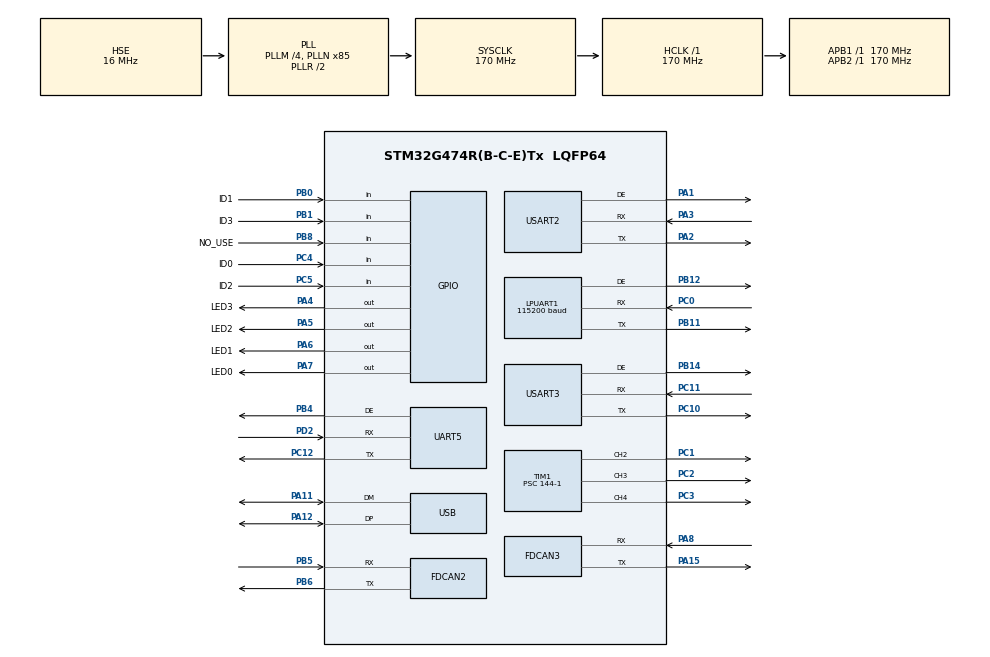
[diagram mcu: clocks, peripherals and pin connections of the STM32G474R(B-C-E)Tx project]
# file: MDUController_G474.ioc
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FDCAN2.CalculateBaudRateNominal=999999
FDCAN2.CalculateTimeBitNominal=1000
FDCAN2.CalculateTimeQuantumNominal=29.411764705882355
FDCAN2.ExtFiltersNbr=1
FDCAN2.Mode=FDCAN_MODE_NORMAL
FDCAN2.NominalPrescaler=5
FDCAN2.NominalTimeSeg1=19
FDCAN2.NominalTimeSeg2=14
FDCAN2.StdFiltersNbr=1
FDCAN3.CalculateBaudRateNominal=999999
FDCAN3.CalculateTimeBitNominal=1000
FDCAN3.CalculateTimeQuantumNominal=29.411764705882355
FDCAN3.ExtFiltersNbr=1
FDCAN3.Mode=FDCAN_MODE_NORMAL
FDCAN3.NominalPrescaler=5
FDCAN3.NominalTimeSeg1=19
FDCAN3.NominalTimeSeg2=14
FDCAN3.StdFiltersNbr=1
LPUART1.BaudRate=115200
Mcu.Family=STM32G4
Mcu.Name=STM32G474R(B-C-E)Tx
Mcu.Package=LQFP64
NVIC.FDCAN2_IT0_IRQn=true\:0\:0\:false\:false\:true\:true\:true\:true
NVIC.FDCAN2_IT1_IRQn=true\:0\:0\:false\:false\:true\:true\:true\:true
NVIC.FDCAN3_IT0_IRQn=true\:0\:0\:false\:false\:true\:true\:true\:true
NVIC.FDCAN3_IT1_IRQn=true\:0\:0\:false\:false\:true\:true\:true\:true
NVIC.LPUART1_IRQn=true\:0\:0\:false\:false\:true\:true\:true\:true
NVIC.PriorityGroup=NVIC_PRIORITYGROUP_4
NVIC.TIM1_BRK_TIM15_IRQn=true\:0\:0\:false\:false\:true\:true\:true\:true
NVIC.TIM1_TRG_COM_TIM17_IRQn=true\:0\:0\:false\:false\:true\:true\:true\:true
NVIC.TIM1_UP_TIM16_IRQn=true\:0\:0\:false\:false\:true\:true\:true\:true
NVIC.TIM2_IRQn=true\:0\:0\:false\:false\:true\:true\:true\:true
NVIC.UART5_IRQn=true\:0\:0\:false\:false\:true\:true\:true\:true
NVIC.USART2_IRQn=true\:0\:0\:false\:false\:true\:true\:true\:true
NVIC.USART3_IRQn=true\:0\:0\:false\:false\:true\:true\:true\:true
NVIC.USB_HP_IRQn=true\:0\:0\:false\:false\:true\:true\:true\:true
NVIC.USB_LP_IRQn=true\:0\:0\:false\:false\:true\:false\:true\:true
PA1.Mode=Hardware Flow Control (RS485)
PA1.Signal=USART2_DE
PA11.Mode=Device
PA11.Signal=USB_DM
PA12.Mode=Device
PA12.Signal=USB_DP
PA13.Signal=SYS_JTMS-SWDIO
PA14.Signal=SYS_JTCK-SWCLK
PA15.Mode=FDCAN_Activate
PA15.Signal=FDCAN3_TX
PA2.Mode=Asynchronous
PA2.Signal=USART2_TX
PA3.Mode=Asynchronous
PA3.Signal=USART2_RX
PA4.GPIO_Label=LED3
PA4.Signal=GPIO_Output
PA5.GPIO_Label=LED2
PA5.Signal=GPIO_Output
PA6.GPIO_Label=LED1
PA6.Signal=GPIO_Output
PA7.GPIO_Label=LED0
PA7.Signal=GPIO_Output
PA8.Mode=FDCAN_Activate
PA8.Signal=FDCAN3_RX
PB0.GPIO_Label=ID1
PB0.GPIO_PuPd=GPIO_PULLUP
PB0.Signal=GPIO_Input
PB1.GPIO_Label=ID3
PB1.GPIO_PuPd=GPIO_PULLUP
PB1.Signal=GPIO_Input
PB11.Mode=Asynchronous
PB11.Signal=LPUART1_TX
PB12.Mode=Hardware Flow Control (RS485)
PB12.Signal=LPUART1_DE
PB14.Mode=Hardware Flow Control (RS485)
PB14.Signal=USART3_DE
PB4.Mode=Hardware Flow Control (RS485)
PB4.Signal=UART5_DE
PB5.Mode=FDCAN_Activate
PB5.Signal=FDCAN2_RX
PB6.Mode=FDCAN_Activate
PB6.Signal=FDCAN2_TX
PB8-BOOT0.GPIO_Label=NO_USE
PB8-BOOT0.GPIO_PuPd=GPIO_NOPULL
PB8-BOOT0.Signal=GPIO_Input
PC0.Mode=Asynchronous
PC0.Signal=LPUART1_RX
PC1.Signal=S_TIM1_CH2
PC10.Mode=Asynchronous
PC10.Signal=USART3_TX
PC11.Mode=Asynchronous
PC11.Signal=USART3_RX
PC12.Mode=Asynchronous
PC12.Signal=UART5_TX
PC2.Signal=S_TIM1_CH3
PC3.Signal=S_TIM1_CH4
PC4.GPIO_Label=ID0
PC4.GPIO_PuPd=GPIO_PULLUP
PC4.Signal=GPIO_Input
PC5.GPIO_Label=ID2
PC5.GPIO_PuPd=GPIO_PULLUP
PC5.Signal=GPIO_Input
PD2.Mode=Asynchronous
PD2.Signal=UART5_RX
PF0-OSC_IN.Mode=HSE-External-Oscillator
PF0-OSC_IN.Signal=RCC_OSC_IN
PF1-OSC_OUT.Mode=HSE-External-Oscillator
PF1-OSC_OUT.Signal=RCC_OSC_OUT
ProjectManager.HeapSize=0x200
ProjectManager.StackSize=0x400
ProjectManager.TargetToolchain=STM32CubeIDE
RCC.ADC12Freq_Value=170000000
RCC.ADC345Freq_Value=170000000
RCC.AHBFreq_Value=170000000
RCC.APB1Freq_Value=170000000
RCC.APB1TimFreq_Value=170000000
RCC.APB2Freq_Value=170000000
RCC.APB2TimFreq_Value=170000000
RCC.CK48CLockSelection=RCC_USBCLKSOURCE_HSI48
RCC.CortexFreq_Value=170000000
RCC.EXTERNAL_CLOCK_VALUE=12288000
RCC.HCLKFreq_Value=170000000
RCC.HSE_VALUE=16000000
RCC.HSI48_VALUE=48000000
RCC.HSI_VALUE=16000000
RCC.LSE_VALUE=32768
RCC.PLLM=RCC_PLLM_DIV4
RCC.PLLN=85
RCC.PLLQ=RCC_PLLQ_DIV6
RCC.PLLSourceVirtual=RCC_PLLSOURCE_HSE
RCC.SYSCLKFreq_VALUE=170000000
RCC.SYSCLKSource=RCC_SYSCLKSOURCE_PLLCLK
RCC.USBFreq_Value=48000000
RCC.VCOOutputFreq_Value=340000000
SH.S_TIM1_CH2.0=TIM1_CH2,PWM Generation2 CH2
SH.S_TIM1_CH3.0=TIM1_CH3,PWM Generation3 CH3
SH.S_TIM1_CH4.0=TIM1_CH4,PWM Generation4 CH4
TIM1.Channel-PWM\ Generation1\ CH1=TIM_CHANNEL_1
TIM1.Channel-PWM\ Generation2\ CH2=TIM_CHANNEL_2
TIM1.Channel-PWM\ Generation3\ CH3=TIM_CHANNEL_3
TIM1.Channel-PWM\ Generation4\ CH4=TIM_CHANNEL_4
TIM1.OCMode_PWM-PWM\ Generation2\ CH2=TIM_OCMODE_PWM2
TIM1.OCMode_PWM-PWM\ Generation3\ CH3=TIM_OCMODE_PWM2
TIM1.OCMode_PWM-PWM\ Generation4\ CH4=TIM_OCMODE_PWM2
TIM1.OCPolarity_2=TIM_OCPOLARITY_LOW
TIM1.OCPolarity_3=TIM_OCPOLARITY_LOW
TIM1.OCPolarity_4=TIM_OCPOLARITY_LOW
TIM1.Prescaler=144-1
TIM15.Prescaler=17000-1
TIM16.Prescaler=17000-1
TIM17.Prescaler=17000-1
TIM2.Prescaler=17000-1
USART2.VirtualMode-Asynchronous=VM_ASYNC
USART2.VirtualMode-Hardware\ Flow\ Control\ (RS485)=VM_ASYNC
USART3.VirtualMode-Asynchronous=VM_ASYNC
USART3.VirtualMode-Hardware\ Flow\ Control\ (RS485)=VM_ASYNC
USB_DEVICE.CLASS_NAME_FS=CDC
USB_DEVICE.LANGID_STRING=1033
USB_DEVICE.MANUFACTURER_STRING=Robopro
USB_DEVICE.PRODUCT_STRING_CDC_FS=MDUController2
USB_DEVICE.VirtualMode=Cdc
USB_DEVICE.VirtualModeFS=Cdc_FS
VP_SYS_VS_DBSignals.Mode=DisableDeadBatterySignals
VP_TIM15_VS_ClockSourceINT.Mode=Internal
VP_TIM16_VS_ClockSourceINT.Mode=Enable_Timer
VP_TIM17_VS_ClockSourceINT.Mode=Enable_Timer
VP_TIM1_VS_ClockSourceINT.Mode=Internal
VP_TIM2_VS_ClockSourceINT.Mode=Internal
VP_USB_DEVICE_VS_USB_DEVICE_CDC_FS.Mode=CDC_FS
board=custom

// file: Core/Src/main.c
/* USER CODE BEGIN Header */
/**
  ******************************************************************************
  * @file           : main.c
  * @brief          : Main program body
  ******************************************************************************
  * @attention
  *
  * Copyright (c) 2025 STMicroelectronics.
  * All rights reserved.
  *
  * This software is licensed under terms that can be found in the LICENSE file
  * in the root directory of this software component.
  * If no LICENSE file comes with this software, it is provided AS-IS.
  *
  ******************************************************************************
  */
/* USER CODE END Header */
#include "main.h"
#include "usb_device.h"

/* USER CODE BEGIN Includes */
#include <stdio.h>
/* USER CODE END Includes */

FDCAN_HandleTypeDef hfdcan2;
FDCAN_HandleTypeDef hfdcan3;

UART_HandleTypeDef hlpuart1;
UART_HandleTypeDef huart5;
UART_HandleTypeDef huart2;
UART_HandleTypeDef huart3;

TIM_HandleTypeDef htim1;
TIM_HandleTypeDef htim2;
TIM_HandleTypeDef htim15;
TIM_HandleTypeDef htim16;
TIM_HandleTypeDef htim17;

void SystemClock_Config(void);
static void MX_GPIO_Init(void);
static void MX_FDCAN2_Init(void);
static void MX_UART5_Init(void);
static void MX_USART2_UART_Init(void);
static void MX_USART3_UART_Init(void);
static void MX_TIM1_Init(void);
static void MX_FDCAN3_Init(void);
static void MX_LPUART1_UART_Init(void);
static void MX_TIM15_Init(void);
static void MX_TIM16_Init(void);
static void MX_TIM17_Init(void);
static void MX_TIM2_Init(void);

int main(void)
{

  /* MCU Configuration--------------------------------------------------------*/

  /* Reset of all peripherals, Initializes the Flash interface and the Systick. */
  HAL_Init();

  /* Configure the system clock */
  SystemClock_Config();

  /* Initialize all configured peripherals */
  MX_GPIO_Init();
  MX_FDCAN2_Init();
  MX_UART5_Init();
  MX_USART2_UART_Init();
  MX_USART3_UART_Init();
  MX_USB_Device_Init();
  MX_TIM1_Init();
  MX_FDCAN3_Init();
  MX_LPUART1_UART_Init();
  MX_TIM15_Init();
  MX_TIM16_Init();
  MX_TIM17_Init();
  MX_TIM2_Init();

  /* Infinite loop */
  while (1)
  {

    /* USER CODE BEGIN 3 */
	  //メインコードはUserLib/board_main.cppに実装
	  cppmain();
  }
  /* USER CODE END 3 */
}

void SystemClock_Config(void)
{
  RCC_OscInitTypeDef RCC_OscInitStruct = {0};
  RCC_ClkInitTypeDef RCC_ClkInitStruct = {0};

  /** Configure the main internal regulator output voltage
  */
  HAL_PWREx_ControlVoltageScaling(PWR_REGULATOR_VOLTAGE_SCALE1_BOOST);

  /** Initializes the RCC Oscillators according to the specified parameters
  * in the RCC_OscInitTypeDef structure.
  */
  RCC_OscInitStruct.OscillatorType = RCC_OSCILLATORTYPE_HSI48|RCC_OSCILLATORTYPE_HSE;
  RCC_OscInitStruct.HSEState = RCC_HSE_ON;
  RCC_OscInitStruct.HSI48State = RCC_HSI48_ON;
  RCC_OscInitStruct.PLL.PLLState = RCC_PLL_ON;
  RCC_OscInitStruct.PLL.PLLSource = RCC_PLLSOURCE_HSE;
  RCC_OscInitStruct.PLL.PLLM = RCC_PLLM_DIV4;
  RCC_OscInitStruct.PLL.PLLN = 85;
  RCC_OscInitStruct.PLL.PLLP = RCC_PLLP_DIV2;
  RCC_OscInitStruct.PLL.PLLQ = RCC_PLLQ_DIV6;
  RCC_OscInitStruct.PLL.PLLR = RCC_PLLR_DIV2;
  if (HAL_RCC_OscConfig(&RCC_OscInitStruct) != HAL_OK)
  {
    Error_Handler();
  }

  /** Initializes the CPU, AHB and APB buses clocks
  */
  RCC_ClkInitStruct.ClockType = RCC_CLOCKTYPE_HCLK|RCC_CLOCKTYPE_SYSCLK
                              |RCC_CLOCKTYPE_PCLK1|RCC_CLOCKTYPE_PCLK2;
  RCC_ClkInitStruct.SYSCLKSource = RCC_SYSCLKSOURCE_PLLCLK;
  RCC_ClkInitStruct.AHBCLKDivider = RCC_SYSCLK_DIV1;
  RCC_ClkInitStruct.APB1CLKDivider = RCC_HCLK_DIV1;
  RCC_ClkInitStruct.APB2CLKDivider = RCC_HCLK_DIV1;

  if (HAL_RCC_ClockConfig(&RCC_ClkInitStruct, FLASH_LATENCY_4) != HAL_OK)
  {
    Error_Handler();
  }
}

static void MX_FDCAN2_Init(void)
{

  hfdcan2.Instance = FDCAN2;
  hfdcan2.Init.ClockDivider = FDCAN_CLOCK_DIV1;
  hfdcan2.Init.FrameFormat = FDCAN_FRAME_CLASSIC;
  hfdcan2.Init.Mode = FDCAN_MODE_NORMAL;
  hfdcan2.Init.AutoRetransmission = DISABLE;
  hfdcan2.Init.TransmitPause = DISABLE;
  hfdcan2.Init.ProtocolException = DISABLE;
  hfdcan2.Init.NominalPrescaler = 5;
  hfdcan2.Init.NominalSyncJumpWidth = 1;
  hfdcan2.Init.NominalTimeSeg1 = 19;
  hfdcan2.Init.NominalTimeSeg2 = 14;
  hfdcan2.Init.DataPrescaler = 1;
  hfdcan2.Init.DataSyncJumpWidth = 1;
  hfdcan2.Init.DataTimeSeg1 = 1;
  hfdcan2.Init.DataTimeSeg2 = 1;
  hfdcan2.Init.StdFiltersNbr = 1;
  hfdcan2.Init.ExtFiltersNbr = 1;
  hfdcan2.Init.TxFifoQueueMode = FDCAN_TX_FIFO_OPERATION;
  if (HAL_FDCAN_Init(&hfdcan2) != HAL_OK)
  {
    Error_Handler();
  }

}

static void MX_FDCAN3_Init(void)
{

  hfdcan3.Instance = FDCAN3;
  hfdcan3.Init.ClockDivider = FDCAN_CLOCK_DIV1;
  hfdcan3.Init.FrameFormat = FDCAN_FRAME_CLASSIC;
  hfdcan3.Init.Mode = FDCAN_MODE_NORMAL;
  hfdcan3.Init.AutoRetransmission = DISABLE;
  hfdcan3.Init.TransmitPause = DISABLE;
  hfdcan3.Init.ProtocolException = DISABLE;
  hfdcan3.Init.NominalPrescaler = 5;
  hfdcan3.Init.NominalSyncJumpWidth = 1;
  hfdcan3.Init.NominalTimeSeg1 = 19;
  hfdcan3.Init.NominalTimeSeg2 = 14;
  hfdcan3.Init.DataPrescaler = 1;
  hfdcan3.Init.DataSyncJumpWidth = 1;
  hfdcan3.Init.DataTimeSeg1 = 1;
  hfdcan3.Init.DataTimeSeg2 = 1;
  hfdcan3.Init.StdFiltersNbr = 1;
  hfdcan3.Init.ExtFiltersNbr = 1;
  hfdcan3.Init.TxFifoQueueMode = FDCAN_TX_FIFO_OPERATION;
  if (HAL_FDCAN_Init(&hfdcan3) != HAL_OK)
  {
    Error_Handler();
  }

}

static void MX_LPUART1_UART_Init(void)
{

  hlpuart1.Instance = LPUART1;
  hlpuart1.Init.BaudRate = 115200;
  hlpuart1.Init.WordLength = UART_WORDLENGTH_8B;
  hlpuart1.Init.StopBits = UART_STOPBITS_1;
  hlpuart1.Init.Parity = UART_PARITY_NONE;
  hlpuart1.Init.Mode = UART_MODE_TX_RX;
  hlpuart1.Init.HwFlowCtl = UART_HWCONTROL_NONE;
  hlpuart1.Init.OneBitSampling = UART_ONE_BIT_SAMPLE_DISABLE;
  hlpuart1.Init.ClockPrescaler = UART_PRESCALER_DIV1;
  hlpuart1.AdvancedInit.AdvFeatureInit = UART_ADVFEATURE_NO_INIT;
  if (HAL_UART_Init(&hlpuart1) != HAL_OK)
  {
    Error_Handler();
  }
  if (HAL_UARTEx_SetTxFifoThreshold(&hlpuart1, UART_TXFIFO_THRESHOLD_1_8) != HAL_OK)
  {
    Error_Handler();
  }
  if (HAL_UARTEx_SetRxFifoThreshold(&hlpuart1, UART_RXFIFO_THRESHOLD_1_8) != HAL_OK)
  {
    Error_Handler();
  }
  if (HAL_UARTEx_DisableFifoMode(&hlpuart1) != HAL_OK)
  {
    Error_Handler();
  }
  if (HAL_RS485Ex_Init(&hlpuart1, UART_DE_POLARITY_HIGH, 0, 0) != HAL_OK)
  {
    Error_Handler();
  }

}

static void MX_UART5_Init(void)
{

  huart5.Instance = UART5;
  huart5.Init.BaudRate = 115200;
  huart5.Init.WordLength = UART_WORDLENGTH_8B;
  huart5.Init.StopBits = UART_STOPBITS_1;
  huart5.Init.Parity = UART_PARITY_NONE;
  huart5.Init.Mode = UART_MODE_TX_RX;
  huart5.Init.HwFlowCtl = UART_HWCONTROL_NONE;
  huart5.Init.OverSampling = UART_OVERSAMPLING_16;
  huart5.Init.OneBitSampling = UART_ONE_BIT_SAMPLE_DISABLE;
  huart5.Init.ClockPrescaler = UART_PRESCALER_DIV1;
  huart5.AdvancedInit.AdvFeatureInit = UART_ADVFEATURE_NO_INIT;
  if (HAL_RS485Ex_Init(&huart5, UART_DE_POLARITY_HIGH, 0, 0) != HAL_OK)
  {
    Error_Handler();
  }
  if (HAL_UARTEx_SetTxFifoThreshold(&huart5, UART_TXFIFO_THRESHOLD_1_8) != HAL_OK)
  {
    Error_Handler();
  }
  if (HAL_UARTEx_SetRxFifoThreshold(&huart5, UART_RXFIFO_THRESHOLD_1_8) != HAL_OK)
  {
    Error_Handler();
  }
  if (HAL_UARTEx_DisableFifoMode(&huart5) != HAL_OK)
  {
    Error_Handler();
  }

}

static void MX_USART2_UART_Init(void)
{

  huart2.Instance = USART2;
  huart2.Init.BaudRate = 115200;
  huart2.Init.WordLength = UART_WORDLENGTH_8B;
  huart2.Init.StopBits = UART_STOPBITS_1;
  huart2.Init.Parity = UART_PARITY_NONE;
  huart2.Init.Mode = UART_MODE_TX_RX;
  huart2.Init.HwFlowCtl = UART_HWCONTROL_NONE;
  huart2.Init.OverSampling = UART_OVERSAMPLING_16;
  huart2.Init.OneBitSampling = UART_ONE_BIT_SAMPLE_DISABLE;
  huart2.Init.ClockPrescaler = UART_PRESCALER_DIV1;
  huart2.AdvancedInit.AdvFeatureInit = UART_ADVFEATURE_NO_INIT;
  if (HAL_RS485Ex_Init(&huart2, UART_DE_POLARITY_HIGH, 0, 0) != HAL_OK)
  {
    Error_Handler();
  }
  if (HAL_UARTEx_SetTxFifoThreshold(&huart2, UART_TXFIFO_THRESHOLD_1_8) != HAL_OK)
  {
    Error_Handler();
  }
  if (HAL_UARTEx_SetRxFifoThreshold(&huart2, UART_RXFIFO_THRESHOLD_1_8) != HAL_OK)
  {
    Error_Handler();
  }
  if (HAL_UARTEx_DisableFifoMode(&huart2) != HAL_OK)
  {
    Error_Handler();
  }

}

static void MX_USART3_UART_Init(void)
{

  huart3.Instance = USART3;
  huart3.Init.BaudRate = 115200;
  huart3.Init.WordLength = UART_WORDLENGTH_8B;
  huart3.Init.StopBits = UART_STOPBITS_1;
  huart3.Init.Parity = UART_PARITY_NONE;
  huart3.Init.Mode = UART_MODE_TX_RX;
  huart3.Init.HwFlowCtl = UART_HWCONTROL_NONE;
  huart3.Init.OverSampling = UART_OVERSAMPLING_16;
  huart3.Init.OneBitSampling = UART_ONE_BIT_SAMPLE_DISABLE;
  huart3.Init.ClockPrescaler = UART_PRESCALER_DIV1;
  huart3.AdvancedInit.AdvFeatureInit = UART_ADVFEATURE_NO_INIT;
  if (HAL_RS485Ex_Init(&huart3, UART_DE_POLARITY_HIGH, 0, 0) != HAL_OK)
  {
    Error_Handler();
  }
  if (HAL_UARTEx_SetTxFifoThreshold(&huart3, UART_TXFIFO_THRESHOLD_1_8) != HAL_OK)
  {
    Error_Handler();
  }
  if (HAL_UARTEx_SetRxFifoThreshold(&huart3, UART_RXFIFO_THRESHOLD_1_8) != HAL_OK)
  {
    Error_Handler();
  }
  if (HAL_UARTEx_DisableFifoMode(&huart3) != HAL_OK)
  {
    Error_Handler();
  }

}

static void MX_TIM1_Init(void)
{

  TIM_ClockConfigTypeDef sClockSourceConfig = {0};
  TIM_MasterConfigTypeDef sMasterConfig = {0};
  TIM_OC_InitTypeDef sConfigOC = {0};
  TIM_BreakDeadTimeConfigTypeDef sBreakDeadTimeConfig = {0};

  htim1.Instance = TIM1;
  htim1.Init.Prescaler = 144-1;
  htim1.Init.CounterMode = TIM_COUNTERMODE_UP;
  htim1.Init.Period = 65535;
  htim1.Init.ClockDivision = TIM_CLOCKDIVISION_DIV1;
  htim1.Init.RepetitionCounter = 0;
  htim1.Init.AutoReloadPreload = TIM_AUTORELOAD_PRELOAD_DISABLE;
  if (HAL_TIM_Base_Init(&htim1) != HAL_OK)
  {
    Error_Handler();
  }
  sClockSourceConfig.ClockSource = TIM_CLOCKSOURCE_INTERNAL;
  if (HAL_TIM_ConfigClockSource(&htim1, &sClockSourceConfig) != HAL_OK)
  {
    Error_Handler();
  }
  if (HAL_TIM_PWM_Init(&htim1) != HAL_OK)
  {
    Error_Handler();
  }
  sMasterConfig.MasterOutputTrigger = TIM_TRGO_RESET;
  sMasterConfig.MasterOutputTrigger2 = TIM_TRGO2_RESET;
  sMasterConfig.MasterSlaveMode = TIM_MASTERSLAVEMODE_DISABLE;
  if (HAL_TIMEx_MasterConfigSynchronization(&htim1, &sMasterConfig) != HAL_OK)
  {
    Error_Handler();
  }
  sConfigOC.OCMode = TIM_OCMODE_PWM2;
  sConfigOC.Pulse = 0;
  sConfigOC.OCPolarity = TIM_OCPOLARITY_LOW;
  sConfigOC.OCNPolarity = TIM_OCNPOLARITY_HIGH;
  sConfigOC.OCFastMode = TIM_OCFAST_DISABLE;
  sConfigOC.OCIdleState = TIM_OCIDLESTATE_RESET;
  sConfigOC.OCNIdleState = TIM_OCNIDLESTATE_RESET;
  if (HAL_TIM_PWM_ConfigChannel(&htim1, &sConfigOC, TIM_CHANNEL_2) != HAL_OK)
  {
    Error_Handler();
  }
  if (HAL_TIM_PWM_ConfigChannel(&htim1, &sConfigOC, TIM_CHANNEL_3) != HAL_OK)
  {
    Error_Handler();
  }
  if (HAL_TIM_PWM_ConfigChannel(&htim1, &sConfigOC, TIM_CHANNEL_4) != HAL_OK)
  {
    Error_Handler();
  }
  sBreakDeadTimeConfig.OffStateRunMode = TIM_OSSR_DISABLE;
  sBreakDeadTimeConfig.OffStateIDLEMode = TIM_OSSI_DISABLE;
  sBreakDeadTimeConfig.LockLevel = TIM_LOCKLEVEL_OFF;
  sBreakDeadTimeConfig.DeadTime = 0;
  sBreakDeadTimeConfig.BreakState = TIM_BREAK_DISABLE;
  sBreakDeadTimeConfig.BreakPolarity = TIM_BREAKPOLARITY_HIGH;
  sBreakDeadTimeConfig.BreakFilter = 0;
  sBreakDeadTimeConfig.BreakAFMode = TIM_BREAK_AFMODE_INPUT;
  sBreakDeadTimeConfig.Break2State = TIM_BREAK2_DISABLE;
  sBreakDeadTimeConfig.Break2Polarity = TIM_BREAK2POLARITY_HIGH;
  sBreakDeadTimeConfig.Break2Filter = 0;
  sBreakDeadTimeConfig.Break2AFMode = TIM_BREAK_AFMODE_INPUT;
  sBreakDeadTimeConfig.AutomaticOutput = TIM_AUTOMATICOUTPUT_DISABLE;
  if (HAL_TIMEx_ConfigBreakDeadTime(&htim1, &sBreakDeadTimeConfig) != HAL_OK)
  {
    Error_Handler();
  }
  HAL_TIM_MspPostInit(&htim1);

}

static void MX_TIM2_Init(void)
{

  TIM_ClockConfigTypeDef sClockSourceConfig = {0};
  TIM_MasterConfigTypeDef sMasterConfig = {0};

  htim2.Instance = TIM2;
  htim2.Init.Prescaler = 17000-1;
  htim2.Init.CounterMode = TIM_COUNTERMODE_UP;
  htim2.Init.Period = 4294967295;
  htim2.Init.ClockDivision = TIM_CLOCKDIVISION_DIV1;
  htim2.Init.AutoReloadPreload = TIM_AUTORELOAD_PRELOAD_DISABLE;
  if (HAL_TIM_Base_Init(&htim2) != HAL_OK)
  {
    Error_Handler();
  }
  sClockSourceConfig.ClockSource = TIM_CLOCKSOURCE_INTERNAL;
  if (HAL_TIM_ConfigClockSource(&htim2, &sClockSourceConfig) != HAL_OK)
  {
    Error_Handler();
  }
  sMasterConfig.MasterOutputTrigger = TIM_TRGO_RESET;
  sMasterConfig.MasterSlaveMode = TIM_MASTERSLAVEMODE_DISABLE;
  if (HAL_TIMEx_MasterConfigSynchronization(&htim2, &sMasterConfig) != HAL_OK)
  {
    Error_Handler();
  }

}

static void MX_TIM15_Init(void)
{

  TIM_ClockConfigTypeDef sClockSourceConfig = {0};
  TIM_MasterConfigTypeDef sMasterConfig = {0};

  htim15.Instance = TIM15;
  htim15.Init.Prescaler = 17000-1;
  htim15.Init.CounterMode = TIM_COUNTERMODE_UP;
  htim15.Init.Period = 65535;
  htim15.Init.ClockDivision = TIM_CLOCKDIVISION_DIV1;
  htim15.Init.RepetitionCounter = 0;
  htim15.Init.AutoReloadPreload = TIM_AUTORELOAD_PRELOAD_DISABLE;
  if (HAL_TIM_Base_Init(&htim15) != HAL_OK)
  {
    Error_Handler();
  }
  sClockSourceConfig.ClockSource = TIM_CLOCKSOURCE_INTERNAL;
  if (HAL_TIM_ConfigClockSource(&htim15, &sClockSourceConfig) != HAL_OK)
  {
    Error_Handler();
  }
  sMasterConfig.MasterOutputTrigger = TIM_TRGO_RESET;
  sMasterConfig.MasterSlaveMode = TIM_MASTERSLAVEMODE_DISABLE;
  if (HAL_TIMEx_MasterConfigSynchronization(&htim15, &sMasterConfig) != HAL_OK)
  {
    Error_Handler();
  }

}

static void MX_TIM16_Init(void)
{

  htim16.Instance = TIM16;
  htim16.Init.Prescaler = 17000-1;
  htim16.Init.CounterMode = TIM_COUNTERMODE_UP;
  htim16.Init.Period = 65535;
  htim16.Init.ClockDivision = TIM_CLOCKDIVISION_DIV1;
  htim16.Init.RepetitionCounter = 0;
  htim16.Init.AutoReloadPreload = TIM_AUTORELOAD_PRELOAD_DISABLE;
  if (HAL_TIM_Base_Init(&htim16) != HAL_OK)
  {
    Error_Handler();
  }

}

static void MX_TIM17_Init(void)
{

  htim17.Instance = TIM17;
  htim17.Init.Prescaler = 17000-1;
  htim17.Init.CounterMode = TIM_COUNTERMODE_UP;
  htim17.Init.Period = 65535;
  htim17.Init.ClockDivision = TIM_CLOCKDIVISION_DIV1;
  htim17.Init.RepetitionCounter = 0;
  htim17.Init.AutoReloadPreload = TIM_AUTORELOAD_PRELOAD_DISABLE;
  if (HAL_TIM_Base_Init(&htim17) != HAL_OK)
  {
    Error_Handler();
  }

}

static void MX_GPIO_Init(void)
{
  GPIO_InitTypeDef GPIO_InitStruct = {0};

  /* GPIO Ports Clock Enable */
  __HAL_RCC_GPIOF_CLK_ENABLE();
  __HAL_RCC_GPIOC_CLK_ENABLE();
  __HAL_RCC_GPIOA_CLK_ENABLE();
  __HAL_RCC_GPIOB_CLK_ENABLE();
  __HAL_RCC_GPIOD_CLK_ENABLE();

  /*Configure GPIO pin Output Level */
  HAL_GPIO_WritePin(GPIOA, LED3_Pin|LED2_Pin|LED1_Pin|LED0_Pin, GPIO_PIN_RESET);

  /*Configure GPIO pins : LED3_Pin LED2_Pin LED1_Pin LED0_Pin */
  GPIO_InitStruct.Pin = LED3_Pin|LED2_Pin|LED1_Pin|LED0_Pin;
  GPIO_InitStruct.Mode = GPIO_MODE_OUTPUT_PP;
  GPIO_InitStruct.Pull = GPIO_NOPULL;
  GPIO_InitStruct.Speed = GPIO_SPEED_FREQ_LOW;
  HAL_GPIO_Init(GPIOA, &GPIO_InitStruct);

  /*Configure GPIO pins : ID0_Pin ID2_Pin */
  GPIO_InitStruct.Pin = ID0_Pin|ID2_Pin;
  GPIO_InitStruct.Mode = GPIO_MODE_INPUT;
  GPIO_InitStruct.Pull = GPIO_PULLUP;
  HAL_GPIO_Init(GPIOC, &GPIO_InitStruct);

  /*Configure GPIO pins : ID1_Pin ID3_Pin */
  GPIO_InitStruct.Pin = ID1_Pin|ID3_Pin;
  GPIO_InitStruct.Mode = GPIO_MODE_INPUT;
  GPIO_InitStruct.Pull = GPIO_PULLUP;
  HAL_GPIO_Init(GPIOB, &GPIO_InitStruct);

  /*Configure GPIO pin : NO_USE_Pin */
  GPIO_InitStruct.Pin = NO_USE_Pin;
  GPIO_InitStruct.Mode = GPIO_MODE_INPUT;
  GPIO_InitStruct.Pull = GPIO_NOPULL;
  HAL_GPIO_Init(NO_USE_GPIO_Port, &GPIO_InitStruct);

}

void Error_Handler(void)
{
  /* USER CODE BEGIN Error_Handler_Debug */
  /* User can add his own implementation to report the HAL error return state */
	printf("error\r\n");
  __disable_irq();
  while (1)
  {
  }
  /* USER CODE END Error_Handler_Debug */
}
